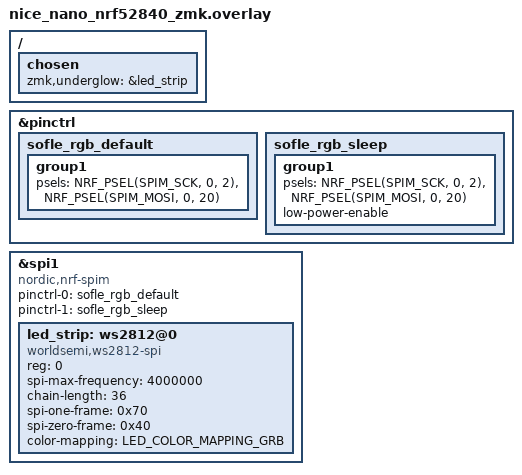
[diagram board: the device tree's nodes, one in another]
#include <zephyr/dt-bindings/pinctrl/nrf-pinctrl.h>

/ {
    chosen {
        zmk,underglow = &led_strip;
    };
};

&pinctrl {
    sofle_rgb_default: sofle_rgb_default {
        group1 {
            psels =
                <NRF_PSEL(SPIM_SCK, 0, 2)>,
                <NRF_PSEL(SPIM_MOSI, 0, 20)>;
        };
    };

    sofle_rgb_sleep: sofle_rgb_sleep {
        group1 {
            psels =
                <NRF_PSEL(SPIM_SCK, 0, 2)>,
                <NRF_PSEL(SPIM_MOSI, 0, 20)>;
            low-power-enable;
        };
    };
};

&spi1 {
    compatible = "nordic,nrf-spim";
    status = "okay";

    pinctrl-0 = <&sofle_rgb_default>;
    pinctrl-1 = <&sofle_rgb_sleep>;
    pinctrl-names = "default", "sleep";

    led_strip: ws2812@0 {
        compatible = "worldsemi,ws2812-spi";

        reg = <0>;
        spi-max-frequency = <4000000>;

        chain-length = <36>;

        spi-one-frame = <0x70>;
        spi-zero-frame = <0x40>;

        color-mapping = <LED_COLOR_MAPPING_GRB>;

        status = "okay";
    };
};
